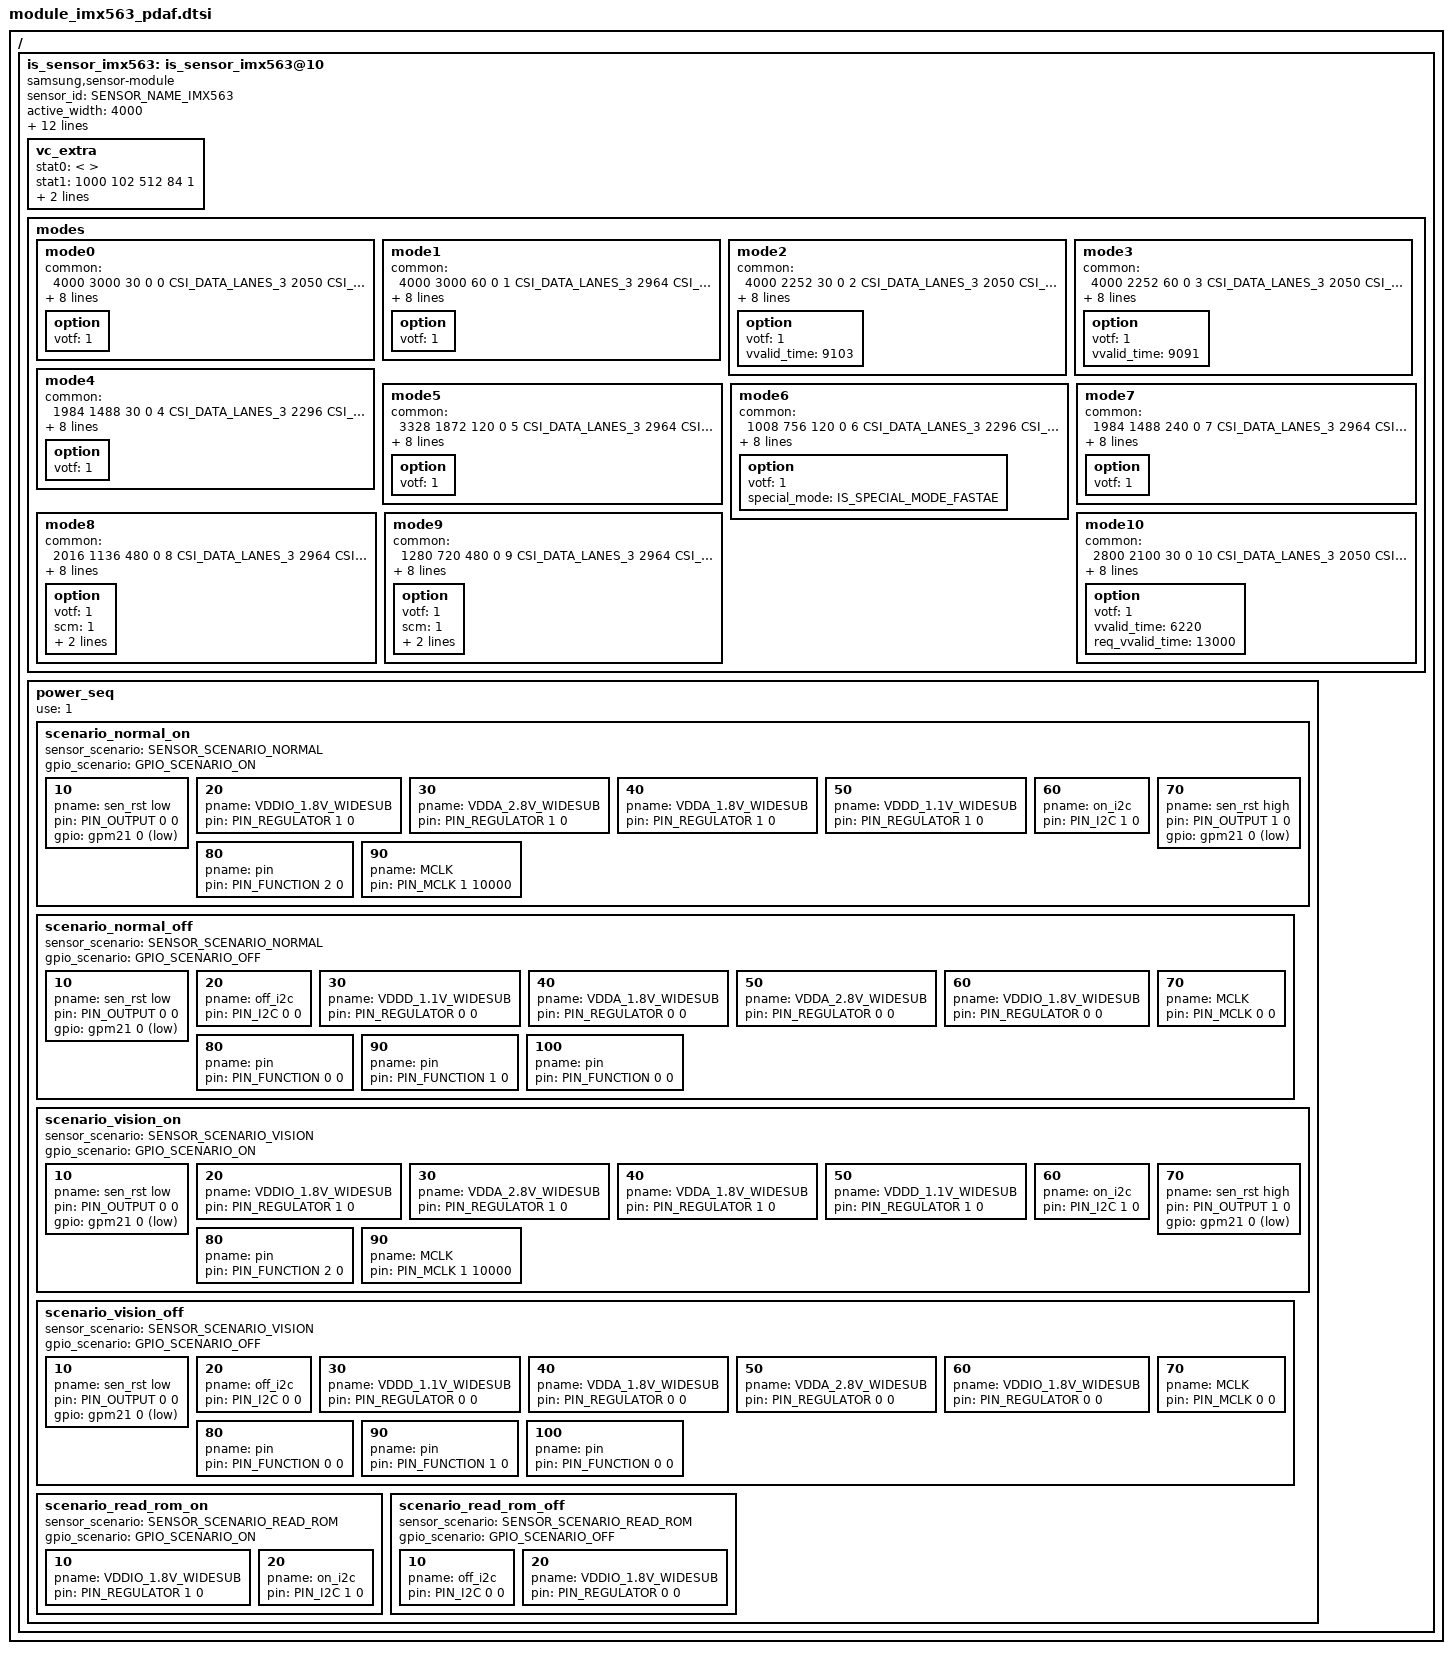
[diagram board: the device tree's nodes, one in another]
/*
 * SAMSUNG EXYNOSxxxx board camera device tree source
 *
 * Copyright (c) 2019 Samsung Electronics Co., Ltd.
 *		http://www.samsung.com
 *
 * This program is free software; you can redistribute it and/or modify
 * it under the terms of the GNU General Public License version 2 as
 * published by the Free Software Foundation.
 */

#include <dt-bindings/camera/exynos_is_dt.h>

/ {
	fragment@camera {
		target-path = "/";
		__overlay__ {
			is_sensor_imx563: is_sensor_imx563@10 {
				compatible = "samsung,sensor-module";

				/* common */
				sensor_id = <SENSOR_NAME_IMX563>;
				active_width = <4000>;
				active_height = <3000>;
				margin_left = <0>;
				margin_right = <0>;
				margin_top = <0>;
				margin_bottom = <0>;
				max_framerate = <480>;
				bitwidth = <10>;
				use_retention_mode = <SENSOR_RETENTION_UNSUPPORTED>;
				sensor_maker = "SONY";
				sensor_name = "IMX563";
				setfile_name = "setfile_imx563.bin";

				status = "okay";

				vc_extra {
					/* ex) statX = <stat_type, sensor_mode, max_width, max_height, max_element> */
					stat0 = </* not avaliable */>;									/* VC_BUF_DATA_TYPE_SENSOR_STAT1 */
					stat1 = </*VC_STAT_TYPE_PDP_3_1_PDAF_STAT0*/ 1000 /*VC_SENSOR_MODE_2PD_MODE3*/ 102 512 84 1>;	/* VC_BUF_DATA_TYPE_GENERAL_STAT1 */
					stat2 = </* not avaliable */>;									/* VC_BUF_DATA_TYPE_SENSOR_STAT2 */
					stat3 = </*VC_STAT_TYPE_PDP_3_1_PDAF_STAT1*/ 1001 /*VC_SENSOR_MODE_2PD_MODE3*/ 102 512 84 1>;	/* VC_BUF_DATA_TYPE_GENERAL_STAT2 */
				};

				/* sensor modes */
				/*
					SENSOR_IMX563_4000X3000_30FPS = 0,
					SENSOR_IMX563_4000X3000_60FPS = 1,
					SENSOR_IMX563_4000X2252_30FPS = 2,
					SENSOR_IMX563_4000X2252_60FPS = 3,
					SENSOR_IMX563_1984X1488_30FPS = 4,
					SENSOR_IMX563_3328X1872_120FPS = 5,
					SENSOR_IMX563_1008X756_120FPS = 6,
					SENSOR_IMX563_1984X1488_240FPS = 7,
					SENSOR_IMX563_2016X1136_480FPS = 8,
					SENSOR_IMX563_1280X720_480FPS = 9,
					SENSOR_IMX563_2800X2100_30FPS = 10,
				*/
				modes {
						/* common = <width, height, fps, settle, mode, lane, speed, interleave, lrte, pd_mode> */
						/* vcX = <map, hwformat, width, height, hwformat, type, width, height> */
					mode0 {/* 7b_2 */
						common = <4000 3000 30 0 0 CSI_DATA_LANES_3 2050 CSI_MODE_VC_ONLY LRTE_ENABLE PD_MOD3>;
						vc0 = </* in */ 0 HW_FORMAT_RAW10 4000 3000	/* out */ HW_FORMAT_RAW10 VC_NOTHING 4000 3000>;
						vc1 = </* in */ 1 HW_FORMAT_RAW10 4000 750	/* out */ HW_FORMAT_RAW10 VC_TAILPDAF 4000 750>;
						vc2 = </* in */ 2 HW_FORMAT_UNKNOWN 0 0		/* out */ HW_FORMAT_UNKNOWN VC_NOTHING 0 0>;
						vc3 = </* in */ 3 HW_FORMAT_UNKNOWN 0 0		/* out */ HW_FORMAT_UNKNOWN VC_NOTHING 0 0>;
						option { votf = <1>; };
					};
					mode1 {/* 7a_3 */
						common = <4000 3000 60 0 1 CSI_DATA_LANES_3 2964 CSI_MODE_VC_ONLY LRTE_ENABLE PD_MOD3>;
						vc0 = </* in */ 0 HW_FORMAT_RAW10 4000 3000	/* out */ HW_FORMAT_RAW10 VC_NOTHING 4000 3000>;
						vc1 = </* in */ 1 HW_FORMAT_RAW10 4000 750	/* out */ HW_FORMAT_RAW10 VC_TAILPDAF 4000 750>;
						vc2 = </* in */ 2 HW_FORMAT_UNKNOWN 0 0		/* out */ HW_FORMAT_UNKNOWN VC_NOTHING 0 0>;
						vc3 = </* in */ 3 HW_FORMAT_UNKNOWN 0 0		/* out */ HW_FORMAT_UNKNOWN VC_NOTHING 0 0>;
						option { votf = <1>; };
					};
					mode2 {/* 8b_2 */
						common = <4000 2252 30 0 2 CSI_DATA_LANES_3 2050 CSI_MODE_VC_ONLY LRTE_ENABLE PD_MOD3>;
						vc0 = </* in */ 0 HW_FORMAT_RAW10 4000 2252	/* out */ HW_FORMAT_RAW10 VC_NOTHING 4000 2252>;
						vc1 = </* in */ 1 HW_FORMAT_RAW10 4000 563	/* out */ HW_FORMAT_RAW10 VC_TAILPDAF 4000 563>;
						vc2 = </* in */ 2 HW_FORMAT_UNKNOWN 0 0		/* out */ HW_FORMAT_UNKNOWN VC_NOTHING 0 0>;
						vc3 = </* in */ 3 HW_FORMAT_UNKNOWN 0 0		/* out */ HW_FORMAT_UNKNOWN VC_NOTHING 0 0>;
						option { votf = <1>; vvalid_time = <9103>; };
					};
					mode3 {/* 9b_2 */
						common = <4000 2252 60 0 3 CSI_DATA_LANES_3 2050 CSI_MODE_VC_ONLY LRTE_ENABLE PD_MOD3>;
						vc0 = </* in */ 0 HW_FORMAT_RAW10 4000 2252	/* out */ HW_FORMAT_RAW10 VC_NOTHING 4000 2252>;
						vc1 = </* in */ 1 HW_FORMAT_RAW10 4000 563	/* out */ HW_FORMAT_RAW10 VC_TAILPDAF 4000 563>;
						vc2 = </* in */ 2 HW_FORMAT_UNKNOWN 0 0		/* out */ HW_FORMAT_UNKNOWN VC_NOTHING 0 0>;
						vc3 = </* in */ 3 HW_FORMAT_UNKNOWN 0 0		/* out */ HW_FORMAT_UNKNOWN VC_NOTHING 0 0>;
						option { votf = <1>; vvalid_time = <9091>; };
					};
					mode4 {/* 10_3 */
						common = <1984 1488 30 0 4 CSI_DATA_LANES_3 2296 CSI_MODE_VC_ONLY LRTE_ENABLE PD_NONE>;
						vc0 = </* in */ 0 HW_FORMAT_RAW10 1984 1488	/* out */ HW_FORMAT_RAW10 VC_NOTHING 1984 1488>;
						vc1 = </* in */ 1 HW_FORMAT_UNKNOWN 0 0		/* out */ HW_FORMAT_UNKNOWN VC_NOTHING 0 0>;
						vc2 = </* in */ 2 HW_FORMAT_UNKNOWN 0 0		/* out */ HW_FORMAT_UNKNOWN VC_NOTHING 0 0>;
						vc3 = </* in */ 3 HW_FORMAT_UNKNOWN 0 0		/* out */ HW_FORMAT_UNKNOWN VC_NOTHING 0 0>;
						option { votf = <1>; };
					};
					mode5 {/* 15_3 */
						common = <3328 1872 120 0 5 CSI_DATA_LANES_3 2964 CSI_MODE_VC_ONLY LRTE_ENABLE PD_MOD3>;
						vc0 = </* in */ 0 HW_FORMAT_RAW10 3328 1872	/* out */ HW_FORMAT_RAW10 VC_NOTHING 3328 1872>;
						vc1 = </* in */ 1 HW_FORMAT_RAW10 3328 468	/* out */ HW_FORMAT_RAW10 VC_TAILPDAF 3328 468>;
						vc2 = </* in */ 2 HW_FORMAT_UNKNOWN 0 0		/* out */ HW_FORMAT_UNKNOWN VC_NOTHING 0 0>;
						vc3 = </* in */ 3 HW_FORMAT_UNKNOWN 0 0		/* out */ HW_FORMAT_UNKNOWN VC_NOTHING 0 0>;
						option { votf = <1>; };
					};
					mode6 {/* 11_3 */
						common = <1008 756 120 0 6 CSI_DATA_LANES_3 2296 CSI_MODE_VC_ONLY LRTE_ENABLE PD_MOD3>;
						vc0 = </* in */ 0 HW_FORMAT_RAW10 1008 756	/* out */ HW_FORMAT_RAW10 VC_NOTHING 1008 756>;
						vc1 = </* in */ 1 HW_FORMAT_RAW10 1008 189	/* out */ HW_FORMAT_RAW10 VC_TAILPDAF 1008 189>;
						vc2 = </* in */ 2 HW_FORMAT_UNKNOWN 0 0		/* out */ HW_FORMAT_UNKNOWN VC_NOTHING 0 0>;
						vc3 = </* in */ 3 HW_FORMAT_UNKNOWN 0 0		/* out */ HW_FORMAT_UNKNOWN VC_NOTHING 0 0>;
						option { votf = <1>; special_mode = <IS_SPECIAL_MODE_FASTAE>; };
					};
					mode7 {/* 12_1 */
						common = <1984 1488 240 0 7 CSI_DATA_LANES_3 2964 CSI_MODE_VC_ONLY LRTE_ENABLE PD_MOD3>;
						vc0 = </* in */ 0 HW_FORMAT_RAW10 1984 1488	/* out */ HW_FORMAT_RAW10 VC_NOTHING 1984 1488>;
						vc1 = </* in */ 1 HW_FORMAT_RAW10 1984 372	/* out */ HW_FORMAT_RAW10 VC_TAILPDAF 1984 372>;
						vc2 = </* in */ 2 HW_FORMAT_UNKNOWN 0 0		/* out */ HW_FORMAT_UNKNOWN VC_NOTHING 0 0>;
						vc3 = </* in */ 3 HW_FORMAT_UNKNOWN 0 0		/* out */ HW_FORMAT_UNKNOWN VC_NOTHING 0 0>;
						option { votf = <1>; };
					};
					mode8 {/* 13_1 */
						common = <2016 1136 480 0 8 CSI_DATA_LANES_3 2964 CSI_MODE_VC_DT LRTE_ENABLE PD_NONE EX_DUALFPS_480>;
						vc0 = </* in */ 0 HW_FORMAT_RAW10 2016 1136	/* out */ HW_FORMAT_RAW10 VC_NOTHING 2016 568>;
						vc1 = </* in */ 1 HW_FORMAT_UNKNOWN 0 0		/* out */ HW_FORMAT_UNKNOWN VC_NOTHING 0 0>;
						vc2 = </* in */ 0 HW_FORMAT_EMBEDDED_8BIT 2520 2	/* out */ HW_FORMAT_EMBEDDED_8BIT VC_EMBEDDED 2520 2>;
						vc3 = </* in */ 2 HW_FORMAT_UNKNOWN 0 0		/* out */ HW_FORMAT_UNKNOWN VC_NOTHING 0 0>;
						option { votf = <1>; scm = <1>; vvalid_time = <1683>; fid_loc = <0 33>; };
					};
					mode9 {/* 16_1 */
						common = <1280 720 480 0 9 CSI_DATA_LANES_3 2964 CSI_MODE_VC_DT LRTE_ENABLE PD_NONE EX_DUALFPS_480>;
						vc0 = </* in */ 0 HW_FORMAT_RAW10 1280 720	/* out */ HW_FORMAT_RAW10 VC_NOTHING 1280 360>;
						vc1 = </* in */ 1 HW_FORMAT_UNKNOWN 0 0		/* out */ HW_FORMAT_UNKNOWN VC_NOTHING 0 0>;
						vc2 = </* in */ 0 HW_FORMAT_EMBEDDED_8BIT 1600 2	/* out */ HW_FORMAT_EMBEDDED_8BIT VC_EMBEDDED 1600 2>;
						vc3 = </* in */ 3 HW_FORMAT_UNKNOWN 0 0		/* out */ HW_FORMAT_UNKNOWN VC_NOTHING 0 0>;
						option { votf = <1>; scm = <1>; vvalid_time = <1123>; fid_loc = <0 33>; };
					};
					mode10 {/* 7b_2_t1 */
						common = <2800 2100 30 0 10 CSI_DATA_LANES_3 2050 CSI_MODE_VC_ONLY LRTE_ENABLE PD_MOD3>;
						vc0 = </* in */ 0 HW_FORMAT_RAW10 2800 2100	/* out */ HW_FORMAT_RAW10 VC_NOTHING 2800 2100>;
						vc1 = </* in */ 1 HW_FORMAT_RAW10 2800 525	/* out */ HW_FORMAT_RAW10 VC_TAILPDAF 2800 525>;
						vc2 = </* in */ 2 HW_FORMAT_UNKNOWN 0 0		/* out */ HW_FORMAT_UNKNOWN VC_NOTHING 0 0>;
						vc3 = </* in */ 3 HW_FORMAT_UNKNOWN 0 0		/* out */ HW_FORMAT_UNKNOWN VC_NOTHING 0 0>;
						option { votf = <1>; vvalid_time = <6220>; req_vvalid_time = <13000>; };
					};
				};

				power_seq {
					use = <1>;
					scenario_normal_on {
						sensor_scenario = <SENSOR_SCENARIO_NORMAL>;
						gpio_scenario = <GPIO_SCENARIO_ON>;

						/* A start node number should be over the 10 for reserved number 0~9. */
						/* pname = "name"; pin = <act value dealy voltage>; gpio = <gpx# # 0x1>; */
						10 { pname = "sen_rst low"; pin = <PIN_OUTPUT 0 0>; gpio = <&gpm21 0 0x1>; };
						20 { pname = "VDDIO_1.8V_WIDESUB"; pin = <PIN_REGULATOR 1 0>; };
						30 { pname = "VDDA_2.8V_WIDESUB"; pin = <PIN_REGULATOR 1 0>; };
						40 { pname = "VDDA_1.8V_WIDESUB"; pin = <PIN_REGULATOR 1 0>; };
						50 { pname = "VDDD_1.1V_WIDESUB"; pin = <PIN_REGULATOR 1 0>; };
						60 { pname = "on_i2c"; pin = <PIN_I2C 1 0>; };
						70 { pname = "sen_rst high"; pin = <PIN_OUTPUT 1 0>; gpio = <&gpm21 0 0x1>; };
						80 { pname = "pin"; pin = <PIN_FUNCTION 2 0>; };
						90 { pname = "MCLK"; pin = <PIN_MCLK 1 10000>; };
					};

					scenario_normal_off {
						sensor_scenario = <SENSOR_SCENARIO_NORMAL>;
						gpio_scenario = <GPIO_SCENARIO_OFF>;

						/* A start node number should be over the 10 for reserved number 0~9. */
						/* pname = "name"; pin = <act value dealy voltage>; gpio = <gpx# # 0x1>; */
						10 { pname = "sen_rst low"; pin = <PIN_OUTPUT 0 0>; gpio = <&gpm21 0 0x1>; };
						20 { pname = "off_i2c"; pin = <PIN_I2C 0 0>; };
						30 { pname = "VDDD_1.1V_WIDESUB"; pin = <PIN_REGULATOR 0 0>; };
						40 { pname = "VDDA_1.8V_WIDESUB"; pin = <PIN_REGULATOR 0 0>; };
						50 { pname = "VDDA_2.8V_WIDESUB"; pin = <PIN_REGULATOR 0 0>; };
						60 { pname = "VDDIO_1.8V_WIDESUB"; pin = <PIN_REGULATOR 0 0>; };
						70 { pname = "MCLK"; pin = <PIN_MCLK 0 0>; };
						80 { pname = "pin"; pin = <PIN_FUNCTION 0 0>; };
						90 { pname = "pin"; pin = <PIN_FUNCTION 1 0>; };
						100 { pname = "pin"; pin = <PIN_FUNCTION 0 0>; };
					};

					scenario_vision_on {
						sensor_scenario = <SENSOR_SCENARIO_VISION>;
						gpio_scenario = <GPIO_SCENARIO_ON>;

						/* A start node number should be over the 10 for reserved number 0~9. */
						/* pname = "name"; pin = <act value dealy voltage>; gpio = <gpx# # 0x1>; */
						10 { pname = "sen_rst low"; pin = <PIN_OUTPUT 0 0>; gpio = <&gpm21 0 0x1>; };
						20 { pname = "VDDIO_1.8V_WIDESUB"; pin = <PIN_REGULATOR 1 0>; };
						30 { pname = "VDDA_2.8V_WIDESUB"; pin = <PIN_REGULATOR 1 0>; };
						40 { pname = "VDDA_1.8V_WIDESUB"; pin = <PIN_REGULATOR 1 0>; };
						50 { pname = "VDDD_1.1V_WIDESUB"; pin = <PIN_REGULATOR 1 0>; };
						60 { pname = "on_i2c"; pin = <PIN_I2C 1 0>; };
						70 { pname = "sen_rst high"; pin = <PIN_OUTPUT 1 0>; gpio = <&gpm21 0 0x1>; };
						80 { pname = "pin"; pin = <PIN_FUNCTION 2 0>; };
						90 { pname = "MCLK"; pin = <PIN_MCLK 1 10000>; };
					};

					scenario_vision_off {
						sensor_scenario = <SENSOR_SCENARIO_VISION>;
						gpio_scenario = <GPIO_SCENARIO_OFF>;

						/* A start node number should be over the 10 for reserved number 0~9. */
						/* pname = "name"; pin = <act value dealy voltage>; gpio = <gpx# # 0x1>; */
						10 { pname = "sen_rst low"; pin = <PIN_OUTPUT 0 0>; gpio = <&gpm21 0 0x1>; };
						20 { pname = "off_i2c"; pin = <PIN_I2C 0 0>; };
						30 { pname = "VDDD_1.1V_WIDESUB"; pin = <PIN_REGULATOR 0 0>; };
						40 { pname = "VDDA_1.8V_WIDESUB"; pin = <PIN_REGULATOR 0 0>; };
						50 { pname = "VDDA_2.8V_WIDESUB"; pin = <PIN_REGULATOR 0 0>; };
						60 { pname = "VDDIO_1.8V_WIDESUB"; pin = <PIN_REGULATOR 0 0>; };
						70 { pname = "MCLK"; pin = <PIN_MCLK 0 0>; };
						80 { pname = "pin"; pin = <PIN_FUNCTION 0 0>; };
						90 { pname = "pin"; pin = <PIN_FUNCTION 1 0>; };
						100 { pname = "pin"; pin = <PIN_FUNCTION 0 0>; };
					};

					scenario_read_rom_on {
						sensor_scenario = <SENSOR_SCENARIO_READ_ROM>;
						gpio_scenario = <GPIO_SCENARIO_ON>;

						/* A start node number should be over the 10 for reserved number 0~9. */
						/* pname = "name"; pin = <act value dealy voltage>; gpio = <gpx# # 0x1>; */
						10 { pname = "VDDIO_1.8V_WIDESUB"; pin = <PIN_REGULATOR 1 0>; };
						20 { pname = "on_i2c"; pin = <PIN_I2C 1 0>; };
					};

					scenario_read_rom_off {
						sensor_scenario = <SENSOR_SCENARIO_READ_ROM>;
						gpio_scenario = <GPIO_SCENARIO_OFF>;

						/* A start node number should be over the 10 for reserved number 0~9. */
						/* pname = "name"; pin = <act value dealy voltage>; gpio = <gpx# # 0x1>; */
						10 { pname = "off_i2c"; pin = <PIN_I2C 0 0>; };
						20 { pname = "VDDIO_1.8V_WIDESUB"; pin = <PIN_REGULATOR 0 0>; };
					};
				};
			};
		}; /* end of __overlay__ */
	}; /* end of fragment */
}; /* end of root */
